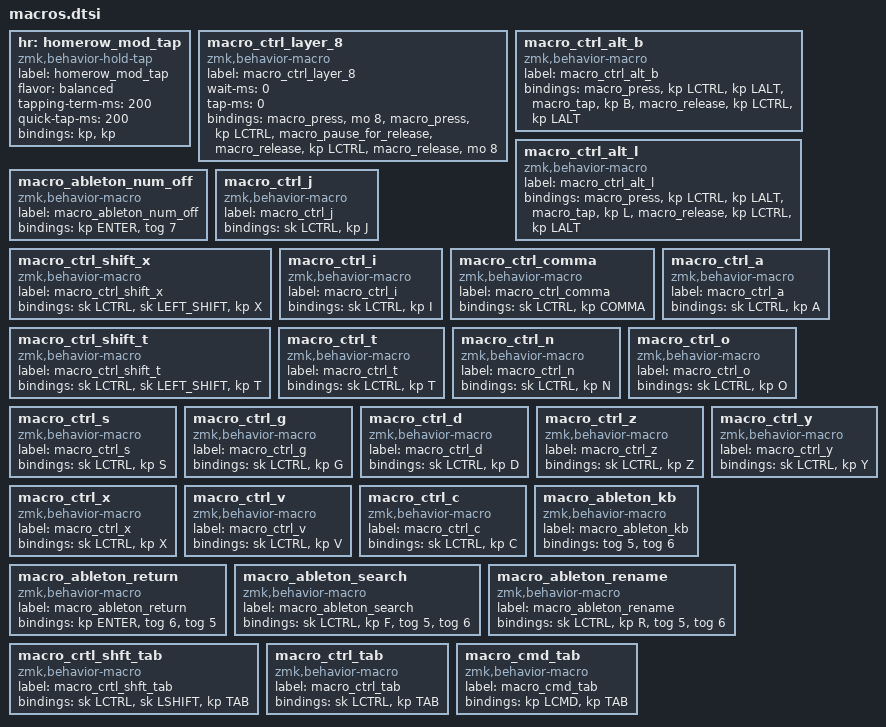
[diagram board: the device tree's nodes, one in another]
/* from https://zmk.dev/docs/behaviors/macros */
hr: homerow_mod_tap {
    compatible = "zmk,behavior-hold-tap";
    label = "homerow_mod_tap";
    #binding-cells = <2>;
    flavor = "balanced";
    tapping-term-ms = <200>;
    quick-tap-ms = <200>;
    bindings = <&kp>, <&kp>;
};

macro_ctrl_layer_8: macro_ctrl_layer_8 {
    compatible = "zmk,behavior-macro";
    label = "macro_ctrl_layer_8";
    wait-ms = <0>;
    tap-ms = <0>;
    #binding-cells = <0>;
    bindings
        = <&macro_press &mo 8>
        , <&macro_press &kp LCTRL>
        , <&macro_pause_for_release>
        , <&macro_release &kp LCTRL>
        , <&macro_release &mo 8>
        ;
};

macro_ctrl_alt_b: macro_ctrl_alt_b{
compatible = "zmk,behavior-macro";
label = "macro_ctrl_alt_b";
#binding-cells = <0>;
bindings
    = <&macro_press &kp LCTRL &kp LALT>
    , <&macro_tap &kp B>
    , <&macro_release &kp LCTRL &kp LALT>
    ;
};
macro_ctrl_alt_l: macro_ctrl_alt_l{
compatible = "zmk,behavior-macro";
label = "macro_ctrl_alt_l";
#binding-cells = <0>;
bindings
    = <&macro_press &kp LCTRL &kp LALT>
    , <&macro_tap &kp L>
    , <&macro_release &kp LCTRL &kp LALT>
    ;
};
macro_ableton_num_off: macro_ableton_num_off{
compatible = "zmk,behavior-macro";
label = "macro_ableton_num_off";
#binding-cells = <0>;
bindings = <&kp ENTER>, <&tog 7>;
};
macro_ctrl_j: macro_ctrl_j{
compatible = "zmk,behavior-macro";
label = "macro_ctrl_j";
#binding-cells = <0>;
bindings = <&sk LCTRL>, <&kp J>;
};
macro_ctrl_shift_x: macro_ctrl_shift_x{
compatible = "zmk,behavior-macro";
label = "macro_ctrl_shift_x";
#binding-cells = <0>;
bindings = <&sk LCTRL>, <&sk LEFT_SHIFT>, <&kp X>;
};
macro_ctrl_i: macro_ctrl_i{
compatible = "zmk,behavior-macro";
label = "macro_ctrl_i";
#binding-cells = <0>;
bindings = <&sk LCTRL>, <&kp I>;
};
macro_ctrl_comma: macro_ctrl_comma{
compatible = "zmk,behavior-macro";
label = "macro_ctrl_comma";
#binding-cells = <0>;
bindings = <&sk LCTRL>, <&kp COMMA>;
};
macro_ctrl_a: macro_ctrl_a{
compatible = "zmk,behavior-macro";
label = "macro_ctrl_a";
#binding-cells = <0>;
bindings = <&sk LCTRL>, <&kp A>;
};
macro_ctrl_shift_t: macro_ctrl_shift_t{
compatible = "zmk,behavior-macro";
label = "macro_ctrl_shift_t";
#binding-cells = <0>;
bindings = <&sk LCTRL>, <&sk LEFT_SHIFT>, <&kp T>;
};
macro_ctrl_t: macro_ctrl_t{
compatible = "zmk,behavior-macro";
label = "macro_ctrl_t";
#binding-cells = <0>;
bindings = <&sk LCTRL>, <&kp T>;
};
macro_ctrl_n: macro_ctrl_n{
compatible = "zmk,behavior-macro";
label = "macro_ctrl_n";
#binding-cells = <0>;
bindings = <&sk LCTRL>, <&kp N>;
};
macro_ctrl_o: macro_ctrl_o{
compatible = "zmk,behavior-macro";
label = "macro_ctrl_o";
#binding-cells = <0>;
bindings = <&sk LCTRL>, <&kp O>;
};
macro_ctrl_s: macro_ctrl_s{
compatible = "zmk,behavior-macro";
label = "macro_ctrl_s";
#binding-cells = <0>;
bindings = <&sk LCTRL>, <&kp S>;
};
macro_ctrl_g: macro_ctrl_g{
compatible = "zmk,behavior-macro";
label = "macro_ctrl_g";
#binding-cells = <0>;
bindings = <&sk LCTRL>, <&kp G>;
};
macro_ctrl_d: macro_ctrl_d{
compatible = "zmk,behavior-macro";
label = "macro_ctrl_d";
#binding-cells = <0>;
bindings = <&sk LCTRL>, <&kp D>;
};
macro_ctrl_z: macro_ctrl_z{
compatible = "zmk,behavior-macro";
label = "macro_ctrl_z";
#binding-cells = <0>;
bindings = <&sk LCTRL>, <&kp Z>;
};
macro_ctrl_y: macro_ctrl_y{
compatible = "zmk,behavior-macro";
label = "macro_ctrl_y";
#binding-cells = <0>;
bindings = <&sk LCTRL>, <&kp Y>;
};
macro_ctrl_x: macro_ctrl_x{
compatible = "zmk,behavior-macro";
label = "macro_ctrl_x";
#binding-cells = <0>;
bindings = <&sk LCTRL>, <&kp X>;
};
macro_ctrl_v: macro_ctrl_v{
compatible = "zmk,behavior-macro";
label = "macro_ctrl_v";
#binding-cells = <0>;
bindings = <&sk LCTRL>, <&kp V>;
};
macro_ctrl_c: macro_ctrl_c{
compatible = "zmk,behavior-macro";
label = "macro_ctrl_c";
#binding-cells = <0>;
bindings = <&sk LCTRL>, <&kp C>;
};
macro_ableton_kb: macro_ableton_kb{
compatible = "zmk,behavior-macro";
label = "macro_ableton_kb";
#binding-cells = <0>;
bindings = <&tog 5>, <&tog 6>;
};
macro_ableton_return: macro_ableton_return{
compatible = "zmk,behavior-macro";
label = "macro_ableton_return";
#binding-cells = <0>;
bindings = <&kp ENTER>, <&tog 6>, <&tog 5>;
};
macro_ableton_search: macro_ableton_search{
compatible = "zmk,behavior-macro";
label = "macro_ableton_search";
#binding-cells = <0>;
bindings = <&sk LCTRL>, <&kp F>, <&tog 5>, <&tog 6>;
};
macro_ableton_rename: macro_ableton_rename{
compatible = "zmk,behavior-macro";
label = "macro_ableton_rename";
#binding-cells = <0>;
bindings = <&sk LCTRL>, <&kp R>, <&tog 5>, <&tog 6>;
};
macro_crtl_shft_tab: macro_crtl_shft_tab{
compatible = "zmk,behavior-macro";
label = "macro_crtl_shft_tab";
#binding-cells = <0>;
bindings = <&sk LCTRL>, <&sk LSHIFT>, <&kp TAB>;
};
macro_ctrl_tab: macro_ctrl_tab{
compatible = "zmk,behavior-macro";
label = "macro_ctrl_tab";
#binding-cells = <0>;
bindings = <&sk LCTRL>, <&kp TAB>;
};
macro_cmd_tab: macro_cmd_tab{
compatible = "zmk,behavior-macro";
label = "macro_cmd_tab";
#binding-cells = <0>;
bindings = <&kp LCMD>, <&kp TAB>;
};
